# USBFS0_1.0 register map
Vendor: Texas Instruments
Registers are 8-bit, read-write, no defined reset value unless marked. A register's access mark holds for its fields unless they carry their own. Offsets are as the file gives them; [hi:lo] are bit positions; lines under a group give offsets from that group; {n}, {i} and the like mark numbered series; 'fields as' and 'values as' point back to an identical list.

## USBFS0 (part 2 of 2)
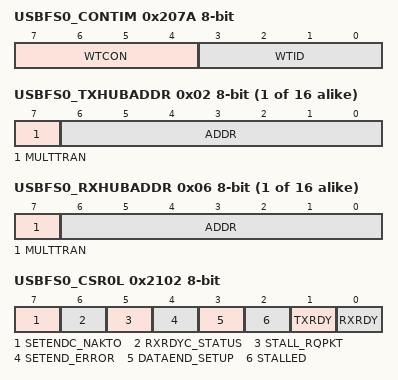
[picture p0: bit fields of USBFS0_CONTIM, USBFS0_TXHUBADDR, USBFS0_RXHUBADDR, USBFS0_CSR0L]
0x207A USBFS0_CONTIM — USB Connect Timing
  [7:4] WTCON — The connect wait field configures the wait required to allow for the user's connect/disconnect filter, in units of 533.3 ns. Note: The default corresponds to 2.667 us.
  [3:0] WTID — The wait ID field configures the delay required from the enable of the ID detection to when the ID value is valid, in units of 4.369 ms. Note: The default corresponds to 52.43 ms.
0x207D USBFS0_FSEOF access not given — USB Full-Speed Last Transaction to End of Frame Timing
0x207E USBFS0_LSEOF access not given — USB Low-Speed Last Transaction to End of Frame Timing
{0x2080+8i} USBFS0_TADDR[{i}] (i=0..15) group — USB Target Address Register for Endpoint [y]
  0x00 USBFS0_TXFUNCADDR — USB Transmit Functional Address Endpoint [n]
    [6:0] ADDR — Device Address specifies the USB bus address for the target Device.
  0x02 USBFS0_TXHUBADDR — USB Transmit Hub Address Endpoint [n]
    [7] MULTTRAN — Record whether the hub has multiple transaction translators.
      0=CLEAR (Clear to indicate that the hub has a single transaction translator.); 1=SET (Set to indicate that the hub has multiple transaction translators.)
    [6:0] ADDR — Device Address specifies the USB bus address for the target Device.
  0x03 USBFS0_TXHUBPORT — USB Transmit Hub Port Endpoint [n]
    [6:0] ADDR — Hub Port specifies the USB hub port number.
  0x04 USBFS0_RXFUNCADDR — USB Receive Functional Address Endpoint [n]
    fields as USBFS0_TADDR[0].USBFS0_TXFUNCADDR
  0x06 USBFS0_RXHUBADDR — USB Receive Hub Address Endpoint [n]
    [7] MULTTRAN — Record whether the hub has multiple transaction translators.
      values as USBFS0_TADDR[0].USBFS0_TXHUBADDR.MULTTRAN
    [6:0] ADDR — Hub Address
  0x07 USBFS0_RXHUBPORT — USB Receive Hub Port Endpoint [n]
    [6:0] ADDR — Hub Address
0x2102 USBFS0_CSR0L — USB Control and Status Endpoint 0 Low
  [7] SETENDC_NAKTO — Setup End Clear / NAK Timeout Device mode: The CPU writes a 1 to this bit to clear the SETEND_ERROR bit. It is cleared automatically. Host mode: This bit will be set when Endpoint 0 is halted following the receipt of NAK responses for longer than the time set by the USBNAKLMT register. The CPU should clear this bit to allow the endpoint to continue.
    0=NO_EFFECT; 1=EFFECT (Clear SETEND_ERROR or SETENDC_KAKTO)
  [6] RXRDYC_STATUS — Receive ready clear / Status packet Device mode: Receive ready clear. The CPU writes a 1 to this bit to clear the RXRDY bit. It is cleared automatically Host mode: Status Packet. The CPU sets this bit at the same time as the TXRDY or STALL_RQPKT bit is set, to perform a status stage transaction. Setting this bit ensures that the DT bit is set in the USBCSRH0 register, so that a DATA1 packet is used for the Status Stage transaction. Setting this bit ensures that the DT bit is set in the USBCSRH0 register so that a DATA1 packet is used for the STATUS stage transaction.
    0=NO_EFFECT (No transaction); 1=EFFECT (Clear RXRDY or sent status packet.)
  [5] STALL_RQPKT — Send Stall / Request Packet. Device mode: The CPU writes a 1 to this bit to terminate the current transaction. The STALL handshake will be transmitted and then this bit will be cleared automatically. Host mode: The CPU sets this bit to request an IN transaction. It is cleared when RXRDY bit is set.
    0=NO_EFFECT; 1=EFFECT (Send stall request or request packet is in effect.)
  [4] SETEND_ERROR — Setup end / Error. Device mode: Setup end. This bit will be set when a control transaction ends before the DATAEND_SETUP bit has been set. An interrupt will be generated and the FIFO flushed at this time. The bit is cleared by the CPU writing a 1 to the SETENDC_NAKTO bit. Host mode: Error indication. This bit will be set when three attempts have been made to perform a transaction with no response from the peripheral. The CPU should clear this bit. An interrupt is generated when this bit is set.
    0=NO_EFFECT (Clear Error. Note: Only effective in host mode.); 1=EFFECT (Setup end / Error indication.)
  [3] DATAEND_SETUP — Data end / Setup Packet. Device mode: Data end bit. The CPU sets this bit: 1. When setting TXRDY for the last data packet. 2. When clearing RXRDY after unloading the last data packet. 3. When setting TXRDY for a zero length data packet. Host mode: Setup packet. The CPU sets this bit, at the same time as the TXRDY bit is set, to send a SETUP token instead of an OUT token for the transaction. Note: Setting this bit always clears the DT bit in the USBCSRH0 register.
    0=EFFECT (No effect); 1=EFFECT (Indicates date end or sends setup token.)
  [2] STALLED — Sent Stall / Receive Stall Device mode: This bit is set when a STALL handshake is transmitted. The CPU should clear this bit. Host mode: This bit is set when a STALL handshake is received. The CPU should clear this bit.
    0=NO_HANDSHAKE (No handshake has been received.); 1=HANDSHAKE (A STALL handshake has been received or transmitted)
  [1] TXRDY — Transmit Packet Ready. Device & Host mode: The CPU sets this bit after loading a data packet into the FIFO. It is cleared automatically when a data packet has been transmitted. An interrupt is also generated at this point (if enabled). Host mode: If both the TXRDY and DATAEND_SETUP bits are set, a setup packet is sent. If just TXRDY is set, an OUT packet is sent.
    0=WAIT (No transmit packet is ready.); 1=READY (Software sets this bit after loading a data packet into the TX FIFO. The EP0 bit in the USBTXIS register is also set in this situation.)
  [0] RXRDY — Receive Packet Ready. Device mode: This bit is set when a data packet has been received. An interrupt is generated when this bit is set. The CPU clears this bit by setting the RXRDYC_STATUS bit. Host mode: Software must clear this bit after he packet has been read from the FIFO to acknowledge that the data has been read from the FIFO.
    0=NO_PACKET (No receive packet has been received.); 1=RECV (Indicates that a data packet has been received in the RX FIFO. The EP0 bit in the USBTXIS register is also set in this situation.)
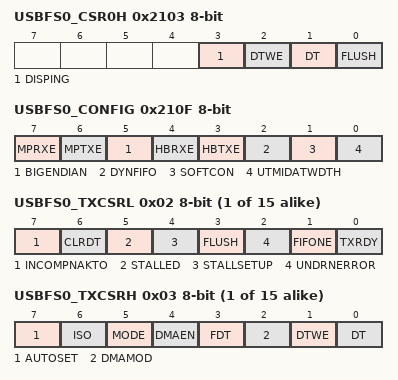
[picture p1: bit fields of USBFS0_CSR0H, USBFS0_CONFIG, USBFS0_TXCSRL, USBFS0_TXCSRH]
0x2103 USBFS0_CSR0H — USB Control and Status Endpoint 0 High
  [3] DISPING — Diable PING tokens in data and status phases of a high-speed Control transfer.
    0=CLR (Ping is allowed.); 1=SET (Ping is not allowed.)
  [2] DTWE — Data Toggle Write Enable. This bit is automatically cleared once the new value is written. Note: This bit is only effective in host mode.
    0=DISABLE (The DT bit cannot be written.); 1=ENABLE (Enables the current state of the endpoint 0 data toggle to be written (see DT bit).)
  [1] DT — Data Toggle. When read, this bit indicates the current state of the endpoint 0 data toggle. If DTWE is set, this bit may be written with the required setting of the data toggle. If DTWE is Low, this bit cannot be written. Care should be taken when writing to this bit as it should only be changed to RESET USB endpoint 0. Note: This bit is only effective in host mode.
    0=LOW (Data toggle is low); 1=HIGH (Data toggle is high)
  [0] FLUSH — Flush FIFO. The CPU writes a 1 to this bit to flush the next packet to be transmitted/read from the Endpoint 0 FIFO. The FIFO pointer is reset and the TXRDY/RXRDY bit in the USBCSRL0 register is cleared. Note: FLUSH should only be used when TXRDY/RXRDY is set. At other times, it may cause data to be corrupted.
    0=NO_EFFECT; 1=EFFECT (Flush the FIFO)
0x2108 USBFS0_COUNT0 ro — USB Receive Byte Count Endpoint 0
  [6:0] COUNT — FIFO Count. COUNT is a read-only value that indicates the number of received data bytes in the endpoint 0 FIFO. The value returned changes as the contents of the FIFO change and is only valid while RXRDY (USBCSRL.RXRDY) is set.
0x210A USBFS0_TYPE0 — USB Type Endpoint 0
  [7:6] SPEED — Operating Speed specifies the operating speed of the target Device. If selected, the target is assumed #br#to have the same connection speed as the USB controller.
    0=UNUSED (Unused (Note: If selected, the target will be assumed to be using the same connection speed as the USB controller.)); 2=FULL (Full-speed); 3=LOW (Low-speed)
0x210B USBFS0_NAKLMT0 — USB NAK Limit Endpoint 0
  [4:0] NAKLMT — EP0 NAK Limit specifies the number of frames after receiving a stream of NAK responses.
0x210F USBFS0_CONFIG ro — USB Config Data
  [7] MPRXE — When set to 1, automatic amalgamation of bulk packets is selected.
  [6] MPTXE — When set to 1, automatic splitting of bulk packets is selected.
  [5] BIGENDIAN — Always '0'. Indicates Little Endian ordering.
  [4] HBRXE — When set to 1 indicates High-bandwidth Rx ISO Endpoint Support selected.
  [3] HBTXE — When set to 1 indicates High-bandwidth TX ISO Endpoint Support selected.
  [2] DYNFIFO — When set to 1 indicates Dynamic FIFO Sizing option selected.
  [1] SOFTCON — Always 1 . Indicates Soft Connect/Disconnect is enabled.
  [0] UTMIDATWDTH — Indicates selected UTMI+ data width. Always 0 indicating 8 bits.
{0x2110+0x10*i} USBFS0_CSR[{i}] (i=0..14) group — USB Control and Status Register for Endpoint [y]
  0x00 USBFS0_TXMAXP 16-bit — USB Maximum Transmit Data Endpoint [n]
    [10:0] MAXLOAD — Maximum Payload specifies the maximum payload in bytes per transaction.
  0x02 USBFS0_TXCSRL — USB Transmit Control and Status Endpoint [n] Low
    [7] INCOMPNAKTO — Incomplete TX / NAK Timeout. Device mode: When the endpoint is being used for high-bandwidth Isochronous, this bit is set to indicate where a large packet has been split into 2 or 3 packets for transmission but insufficient IN tokens have been received to send all the parts. Note: In anything other than isochronous transfers, this bit will always return 0. Host mode - bulk endpoints only: This bit will be set when the TX endpoint is halted following the receipt of NAK responses for longer than the time set as theTXPOLLNAKLMT by the TXINTERVAL register. The CPU should clear this bit to allow the endpoint to continue. Host mode - high-bandwidth Interrupt endpoints only: This bit will be set if no response is received from the device to which the packet is being sent.
      0=CLEAR (No condition present / clear condition.); 1=SET (Condition present.)
    [6] CLRDT — Clear DataToggle. The CPU writes a 1 to this bit to reset the endpoint data toggle to 0. Note: Host and device mode.
      0=NO_EFFECT; 1=EFFECT (Writing a 1 to this bit clears the DT bit in the USBTXCSRH[n] register.)
    [5] STALLED — Sent stall / RX stalled. Device mode: This bit is set when a STALL handshake is transmitted. The FIFO is flushed and the TXRDY bit is cleared. The CPU should clear this bit. Host mode: This bit is set when a STALL handshake is received. When this bit is set, any DMA request that is in progress is stopped, the FIFO is completely flushed and the TXRDY bit is cleared. The CPU should clear this bit.
      0=CLEAR (Clear stall indication.); 1=SET (Indicates that a STALL handshake has been sent or received.)
    [4] STALLSETUP — Send stall / Setup packet request. Device mode: The CPU writes a 1 to this bit to issue a STALL handshake to an IN token. The CPU clears this bit to terminate the stall condition. Note: This bit has no effect where the endpoint is being used for Isochronous transfers. Host mode: The CPU sets this bit, at the same time as the TXRDY bit is set, to send a SETUP token instead of an OUT token for the transaction. Note: Setting this bit also clears the USBTXCSRH.DT register.
      0=CLEAR (No effect); 1=SET (Send stall or setup packet request.)
    [3] FLUSH — Flush FIFO. The CPU writes a 1 to this bit to flush the latest packet from the endpoint TX FIFO. The FIFO pointer is reset, the TXRDY bit is cleared and an interrupt is generated. May be set simultaneously with TXRDY to abort the packet that is currently being loaded into the FIFO. Note: FLUSH should only be used when TXRDY is set. At other times, it may cause data to be corrupted. Also note that, if the FIFO is double-buffered, FLUSH may need to be set twice to completely clear the FIFO. Note: Host and device mode.
      0=NO_EFFECT; 1=EFFECT (Flushes the latest packet from the endpoint transmit FIFO.)
    [2] UNDRNERROR — Underrun / Error condition. Device mode: The USB controller sets this bit if an IN token is received when TXRDY is not set. The CPU should clear this bit. Host mode: The USB controller sets this bit when 3 attempts have been made to send a packet and no handshake packet has been received. When the bit is set, an interrupt is generated, TXRDY is cleared and the FIFO is completely flushed. The CPU should clear this bit. Valid only when the endpoint is operating in Bulk or Interrupt mode.
      0=CLEAR (No underrun or error condition); 1=SET (Underrun or error condition exist.)
    [1] FIFONE — FIFO Not Empty. The USB controller sets this bit when there is at least 1 packet in the TX FIFO. Note: Host and device mode.
      0=EMPTY (The FIFO is empty); 1=NOT_EMPTY (At least one packet is in the transmit FIFO.)
    [0] TXRDY — Transmit Packet Ready. The CPU sets this bit after loading a data packet into the FIFO. This bit is cleared automatically when a data packet has been transmitted. The EPn bit in the USBTXIS register is also set at this point. TXRDY is also automatically cleared prior to loading a second packet into a double-buffered FIFO. Note: Host and device mode
      0=WAIT (No transmit packet is ready.); 1=READY (Software sets this bit after loading a data packet into the TX FIFO.)
  0x03 USBFS0_TXCSRH — USB Transmit Control and Status Endpoint [n] High
    [7] AUTOSET — Auto Set. If the CPU sets this bit, the TXRDY bit will be be automatically set when data of the maximum packet size (value in USBTXMAXP[n]) is loaded into the transmit FIFO. If a packet of less than the maximum packet size is loaded, then the TXRDY bit must be set manually. Note: Should not be set for either high-bandwidth Isochronous endpoints or high-bandwidth Interrupt endpoints. Note: Device and host mode.
      0=MANUAL (The TXRDY bit must be set manually.); 1=AUTO (The TXRDY bit is automatically set when maximum packet size is loaded into the TX FIFO.)
    [6] ISO — Isochronous Transfers. The CPU sets this bit to enable the TX endpoint for Isochronous transfers, and clears it to enable the TX endpoint for Bulk or Interrupt transfers. Note: This bit only has any effect in device mode. In host mode, it always returns zero.
      0=BULK_INT_TRANSFER (Enables the transmit endpoint for bulk or interrupt transfers.); 1=ISO_TRANSFER (Enables the transmit endpoint for isochronous transfers.)
    [5] MODE — Mode The CPU sets this bit to enable the endpoint direction as TX, and clears the bit to enable it as Rx. Note: This bit only has an effect when the same endpoint FIFO is used for both transmit and receive transactions. Note: Host and device mode.
      0=RX (Enables the endpoint direction as RX.); 1=TX (Enables the endpoint direction as TX.)
    [4] DMAEN — DMA Request Enable The CPU sets this bit to enable the DMA request for the TX endpoint. Note: Four TX and four RX endpoints can be connected to the DMA module. If this bit is set for a particular endpoint, the TRIGATX, TRIGBTX, TRIGCTX, or TRIGDTX field in the USB DMA Select (USBDMASEL) register must be programmed correspondingly. Note: Device and host mode.
      0=DISABLE (Disables the DMA request for the transmit endpoint.); 1=ENABLE (Enables the DMA request for the transmit endpoint.)
    [3] FDT — Force Data Toggle. The CPU sets this bit to force the endpoint DT bit to switch and the data packet to be cleared from the FIFO, regardless of whether an ACK was received. This can be used by Interrupt TX endpoints that are used to communicate rate feedback for Isochronous endpoints. Note: This bit should only be set when the TXRDY bit is set. At other times, it may cause data to be corrupted. Note: Device and host mode.
      0=NO_EFFECT; 1=EFFECT (Forces data toggle)
    [2] DMAMOD — DMA Request Mode. The CPU sets this bit to select DMA Request Mode 1 and clears it to select DMA Request Mode 0. Note: This bit must not be cleared either before or in the same cycle as the DMAEN bit is cleared. Note: Device and host mode.
      0=MODE0 (An interrupt is generated after every DMA packet transfer.); 1=MODE1 (An interrupt is generated only after the entire DMA transfer is complete.)
    [1] DTWE — Data Toggle Write Enable. The CPU writes a 1 to this bit to enable the current state of the TX Endpoint data toggle to be written. This bit is automatically cleared once the new value is written. Note: Host mode only.
      0=DISABLE (The DT bit cannot be written.); 1=ENABLE (Enables the current state of the transmit endpoint data to be written (see DT bit).)
    [0] DT — Data Toggle. When read, this bit indicates the current state of the transmit endpoint data toggle. If DTWE is High, this bit can be written with the required setting of the data toggle. If DTWE is Low, any value written to this bit is ignored. Care should be taken when writing to this bit as it should only be changed to RESET the transmit endpoint. Note: Host mode only
      0=LOW (Data toggle is low); 1=HIGH (Data toggle is high)
  0x04 USBFS0_RXMAXP 16-bit — USB Maximum Receive Data Endpoint [n]
    fields as USBFS0_CSR[0].USBFS0_TXMAXP
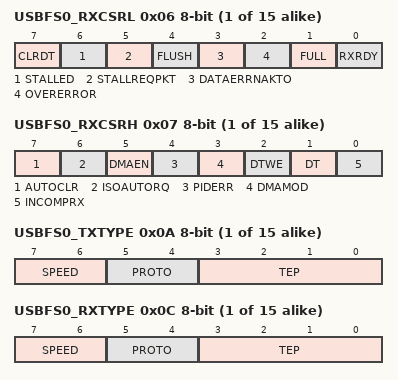
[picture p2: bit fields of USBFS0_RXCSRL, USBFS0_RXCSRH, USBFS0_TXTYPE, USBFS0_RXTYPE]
  0x06 USBFS0_RXCSRL access per field — USB Receive Control and Status Endpoint [n] Low
    [7] CLRDT rw — Clear Data Toggle. The CPU writes a 1 to this bit to reset the endpoint data toggle to 0. Note: Device and host mode.
      0=NO_EFFECT; 1=EFFECT (Writing a 1 to this bit clears the DT bit in the USBRXCSRH[n] register.)
    [6] STALLED rw — Sent Stall / RX Stall Device mode: This bit is set when a STALL handshake is transmitted. The CPU should clear this bit. Host mode: When a STALL handshake is received, this bit is set and an interrupt is generated. The CPU should clear this bit.
      0=STALLED_WAIT (No handshake has been received.); 1=STALLED_RECEIVE (A STALL handshake has been received. The EPn bit in the USBRXIS register is also set.)
    [5] STALLREQPKT rw — Send Stall / Request Packet. Device mode: The CPU writes a 1 to this bit to issue a STALL handshake. The CPU clears this bit to terminate the stall condition. - Note: This bit has no effect where the endpoint is being used for Isochronous transfers. Host mode: The CPU writes a 1 to this bit to request an IN transaction. It is cleared when RXRDY is set.
      0=CLEAR (No effect); 1=SET (Send stall or packet request.)
    [4] FLUSH rw — Flush FIFO. The CPU writes a 1 to this bit to flush the next packet to be read from the endpoint RX FIFO. The FIFO pointer is reset and the RXRDY bit is cleared. Note: Thsi bit should only be set when RXRDY is set. At other times, it may cause data to be corrupted. Note: If the FIFO is double-buffered, FLUSH may need to be set twice to completely clear the FIFO. Note: Device and host mode.
      0=NO_EFFECT; 1=EFFECT (Flushes the next packet to be read from the endpoint receive FIFO. The FIFO pointer is reset and the RXRDY bit is cleared)
    [3] DATAERRNAKTO rw — Data Error / NAK Timeout Device mode: Data Error - This bit is set when RXRDY is set, if the data packet has a CRC or bit-stuff error. It is cleared when RXRDY is cleared. - Note: This bit is only valid when the endpoint is operating in ISO mode. In Bulk mode, it always returns zero. Host mode: NAK Timeout - When operating in ISO mode, this bit is set when RXRDY is set, if the data packet has a CRC or bit-stuff error and cleared when RXRDY is cleared. In Bulk mode, this bit will be set when the Rx endpoint is halted following the receipt of NAK responses for longer than the time set as the NAK Limit by the USBRXINTERVAL register. The CPU should clear this bit to allow the endpoint to continue.
      0=CLEAR (Normal operation); 1=SET (Data error or NAK Timeout condition exist.)
    [2] OVERERROR rw — Over run / Error. Device mode: Over run - This bit is set if an OUT packet cannot be loaded into the receive FIFO. The CPU should clear this bit. - Note: This bit is only valid when the endpoint is operating in ISO mode. In Bulk mode, it always returns zero. Host mode: The USB sets this bit when 3 attempts have been made to receive a packet and no data packet has been received. The CPU should clear this bit. An interrupt is generated when the bit is set. - Note: This bit is only valid when the RX endpoint is operating in Bulk or Interrupt mode. In ISO mode, it always returns zero.
      0=CLEAR (No over run or error condition.); 1=SET (Under run or error condition exist.)
    [1] FULL ro — FIFO Full. This bit is set when no more packets can be loaded into the RX FIFO. Note: Device and host mode.
      0=NO (The receive FIFO is not full.); 1=YES (The receive FIFO is full. No more packets can be loaded into the receive FIFO.)
    [0] RXRDY rw — Receive Packet Ready. This bit is set when a data packet has been received. The CPU should clear this bit when the packet has been unloaded from the Rx FIFO. An interrupt is generated when the bit is set. If the AUTOCLR bit in the USBRXCSRH[n] register is set, then the this bit is automatically cleared when a packet of USBRXMAXP[n] bytes has been unloaded from the receive FIFO. If the AUTOCLR bit is clear, or if packets of less than the maximum packet size are unloaded, then software must clear this bit manually when the packet has been unloaded from the receive FIFO. Note: Device and host mode.
      0=WAIT (No data packet has been received.); 1=READY (Indicates that a data packet has been received. The EP[j] bit in the USBTXIS register is also set in this situation)
  0x07 USBFS0_RXCSRH access per field — USB Receive Control and Status Endpoint [n] High
    [7] AUTOCLR rw — Auto Clear. If the CPU sets this bit then the RXRDY bit will be automatically cleared when a packet of USBRXMAXP bytes has been unloaded from the RX FIFO. When packets of less than the maximum packet size are unloaded, RXRDY will have to be cleared manually. When using a DMA to unload the RX-FIFO, data is read from the RX-FIFO in 4 byte chunks regardless of the USBRXMAXP setting. Note: Device and host mode.
      0=DSIABLE (No effect); 1=ENABLE (Enables the RXRDY bit to be automatically cleared when a packet of USBRXMAXP[n] bytes has been unloaded from the receive FIFO.)
    [6] ISOAUTORQ rw — Isochronous transfer mode / Auto request. Device mode: The CPU sets this bit to enable the Rx endpoint for Isochronous transfers, and clears it to enable the Rx endpoint for Bulk/Interrupt transfers. Host mode: If the CPU sets this bit, the STALLREQPKT bit will be automatically set when the RXRDY bit is cleared. - Note: This bit is automatically cleared when a short packet is received.
      0=DISABLE (No effect); 1=ENABLE (Sets ISO transfer mode or enables the REQPKT bit to be automatically set when the RXRDY bit is cleared.)
    [5] DMAEN rw — DMA Request Enable The CPU sets this bit to enable the DMA request for the Rx endpoint. Note: Four TX and four RX endpoints can be connected to the DMA module. If this bit is set for a particular endpoint, the TRIGARX, TRIGBRX, TRIGCRX, or TRIGDRX field in the USB DMA Select (USBDMASEL) register must be programmed correspondingly
      0=DISABLE (Disables the DMA request for the receive endpoint.); 1=ENABLE (Enables the DMA request for the receive endpoint.)
    [4] PIDERR ro — PID error ISO Transactions: The USB controller sets this bit to indicate a PID error in the received packet. Bulk/Interrupt Transactions: The setting of this bit is ignored. Note: Device and host mode.
      0=NO_ERROR; 1=ERROR (Indicates a PID error in the received packet of an isochronous transaction.)
    [3] DMAMOD rw — DMA request mode The CPU sets this bit to select DMA Request Mode 1 and clears it to select DMA Request Mode 0. Note: This bit must not be cleared either before or in the same cycle as the above DMAEN bit is cleared. Note: Device and host mode.
      values as USBFS0_CSR[0].USBFS0_TXCSRH.DMAMOD
    [2] DTWE rw — Data Toggle Write Enable. The CPU writes a 1 to this bit to enable the current state of the Endpoint 0 data toggle to be written. This bit is automatically cleared once the new value is written. Note: Host mode only.
      0=DISABLE (The DT bit cannot be written.); 1=ENABLE (Enables the current state of the receive endpoint data to be written (see DT bit).)
    [1] DT rw — Data Toggle. When read, this bit indicates the current state of the receive data toggle. If DTWE is High, this bit may be written with the required setting of the data toggle. If DTWE is Low, any value written to this bit is ignored. Care should be taken when writing to this bit as it should only be changed to RESET the receive endpoint. Note: Host mode only.
      0=LOW (Data toggle is low); 1=HIGH (Data toggle is high)
    [0] INCOMPRX rw — This bit will be set in a high-bandwidth Isochronous or Interrupt transfer if the packet received is incomplete, because parts of the data were not received. It is cleared when RXRDY is cleared. Note: In anything other than Isochronous transfer, this bit will always return 0. Note: Device and host mode.
  0x08 USBFS0_RXCOUNT 16-bit ro — USB Receive Byte Count Endpoint [n]
    [12:0] COUNT — Receive Packet Count indicates the number of bytes in the receive packet.
  0x0A USBFS0_TXTYPE — USB Host Transmit Configure Type Endpoint [n]
    [7:6] SPEED — Operating Speed. This bit field specifies the operating speed of the target Device:
      0=DEFAULT (Default. The target is assumed to be using the same connection speed as the USB controller.); 2=FULL (Full speed); 3=LOW (Low speed)
    [5:4] PROTO — Protocol. Software must configure this bit field to select the required protocol for the transmit endpoint:
      0=CTRL (Control); 1=ISO (isochronous); 2=BULK; 3=INT (Interrupt)
    [3:0] TEP — Target Endpoint Number. Software must configure this value to the endpoint number contained in the transmit endpoint descriptor returned to the USB controller during Device enumeration.
  0x0B USBFS0_TXINTERVAL access not given — USB Host Transmit Interval Endpoint [n]
  0x0C USBFS0_RXTYPE — USB Host Configure Receive Type Endpoint [n]
    [7:6] SPEED — Operating Speed. #br#This bit field specifies the operating speed of the target Device:
      values as USBFS0_CSR[0].USBFS0_TXTYPE.SPEED
    [5:4] PROTO — Protocol. Software must configure this bit field to select the required protocol for the transmit endpoint:
      values as USBFS0_CSR[0].USBFS0_TXTYPE.PROTO
    [3:0] TEP — Target Endpoint Number. Software must configure this value to the endpoint number contained in the transmit endpoint descriptor returned to the USB controller during Device enumeration.
  0x0D USBFS0_RXINTERVAL access not given — USB Host Receive Polling Interval Endpoint [n]
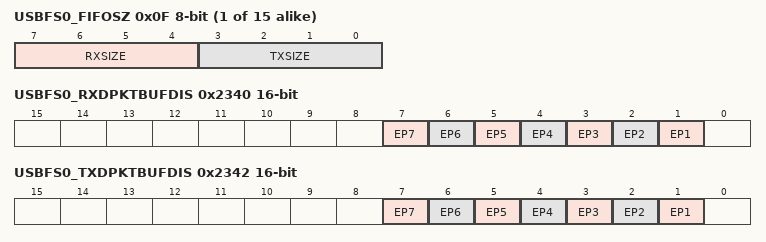
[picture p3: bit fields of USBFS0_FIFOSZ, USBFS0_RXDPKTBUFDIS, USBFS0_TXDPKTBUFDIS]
  0x0F USBFS0_FIFOSZ ro — USB TX and RX FIFO Size Endpoint [n]
    [7:4] RXSIZE — Returns the configured size of the RX FIFO
      0=BYTES_8 (FIFO size 8-byte); 1=BYTES_16 (FIFO size 16-byte); 2=BYTES_32 (FIFO size 32-byte); 3=BYTES_64 (FIFO size 64-byte); 4=BYTES_128 (FIFO size 128-byte); 5=BYTES_256 (FIFO size 256-byte); 6=BYTES_512 (FIFO size 512-byte); 7=BYTES_1024 (FIFO size 1024-byte); 8=BYTES_2048 (FIFO size 2048-byte)
    [3:0] TXSIZE — Returns the configured size of the TX FIFO
      values as RXSIZE
{0x2304+4i} USBFS0_RQPKTCOUNT[{i}] (i=0..14) 32-bit — USB Request Packet Count in Block Transfer Endpoint [n]
  [15:0] COUNT — Block Transfer Packet Count sets the number of packets of the size defined by the MAXLOAD bit field that are to be transferred in a block transfer. Note: This is only used in Host mode when AUTORQ is set. The bit has no effect in Device mode or when AUTORQ is not set.
0x2340 USBFS0_RXDPKTBUFDIS 16-bit ro — USB Receive Double Packet Buffer Disable
  [all] fields
    0=DISABLE (Disables double-packet buffering.); 1=ENABLE (Enables double-packet buffering.)
  [n] EP{n} (n=1..7) — EP{n} RX Double Packet Buffer Disable
0x2342 USBFS0_TXDPKTBUFDIS 16-bit ro — USB Transmit Double Packet Buffer Disable
  [all] fields
    values as the fields of USBFS0_RXDPKTBUFDIS
  [n] EP{n} (n=1..7) — EP{n} TX Double Packet Buffer Disable
